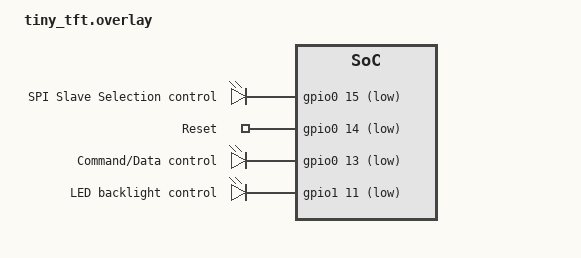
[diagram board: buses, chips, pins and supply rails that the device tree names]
/ {
	aliases {
		tftcs  = &tft0;
		tftrst = &tft1;
		tftdc  = &tft2;
		tftled = &tft3;
	};
	tfts {
		compatible = "gpio-leds";
		tft0: tft_0 {
			gpios = < &gpio0 15 0x1 >;
			label = "SPI Slave Selection control";
		};
		tft1: tft_1 {
			gpios = < &gpio0 14 0x1 >;
			label = "Reset";
		};
		tft2: tft_2 {
			gpios = < &gpio0 13 0x1 >;
			label = "Command/Data control";
		};
		tft3: tft_3 {
			gpios = < &gpio1 11 0x1 >;
			label = "LED backlight control";
		};
	};
};
